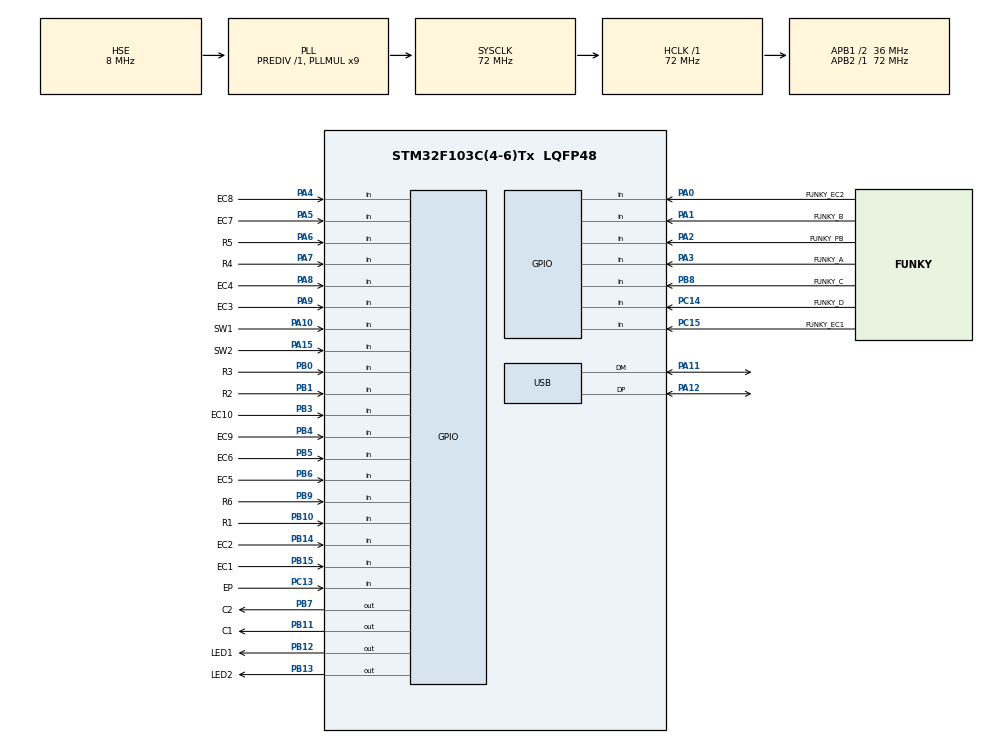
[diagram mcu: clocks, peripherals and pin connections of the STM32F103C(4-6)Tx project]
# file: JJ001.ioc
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Mcu.Family=STM32F1
Mcu.Name=STM32F103C(4-6)Tx
Mcu.Package=LQFP48
NVIC.PriorityGroup=NVIC_PRIORITYGROUP_4
NVIC.USB_LP_CAN1_RX0_IRQn=true\:0\:0\:false\:false\:true\:false\:true\:true
PA0-WKUP.GPIO_Label=FUNKY_EC2
PA0-WKUP.GPIO_PuPd=GPIO_PULLUP
PA0-WKUP.Signal=GPIO_Input
PA1.GPIO_Label=FUNKY_B
PA1.GPIO_PuPd=GPIO_PULLUP
PA1.Signal=GPIO_Input
PA10.GPIO_Label=SW1
PA10.GPIO_PuPd=GPIO_PULLUP
PA10.Signal=GPIO_Input
PA11.Mode=Device
PA11.Signal=USB_DM
PA12.Mode=Device
PA12.Signal=USB_DP
PA15.GPIO_Label=SW2
PA15.GPIO_PuPd=GPIO_PULLUP
PA15.Signal=GPIO_Input
PA2.GPIO_Label=FUNKY_PB
PA2.GPIO_PuPd=GPIO_PULLUP
PA2.Signal=GPIO_Input
PA3.GPIO_Label=FUNKY_A
PA3.GPIO_PuPd=GPIO_PULLUP
PA3.Signal=GPIO_Input
PA4.GPIO_Label=EC8
PA4.GPIO_PuPd=GPIO_PULLUP
PA4.Signal=GPIO_Input
PA5.GPIO_Label=EC7
PA5.GPIO_PuPd=GPIO_PULLUP
PA5.Signal=GPIO_Input
PA6.GPIO_Label=R5
PA6.GPIO_PuPd=GPIO_PULLUP
PA6.Signal=GPIO_Input
PA7.GPIO_Label=R4
PA7.GPIO_PuPd=GPIO_PULLUP
PA7.Signal=GPIO_Input
PA8.GPIO_Label=EC4
PA8.GPIO_PuPd=GPIO_PULLUP
PA8.Signal=GPIO_Input
PA9.GPIO_Label=EC3
PA9.GPIO_PuPd=GPIO_PULLUP
PA9.Signal=GPIO_Input
PB0.GPIO_Label=R3
PB0.GPIO_PuPd=GPIO_PULLUP
PB0.Signal=GPIO_Input
PB1.GPIO_Label=R2
PB1.GPIO_PuPd=GPIO_PULLUP
PB1.Signal=GPIO_Input
PB10.GPIO_Label=R1
PB10.GPIO_PuPd=GPIO_PULLUP
PB10.Signal=GPIO_Input
PB11.GPIO_Label=C1
PB11.GPIO_Speed=GPIO_SPEED_FREQ_HIGH
PB11.Signal=GPIO_Output
PB12.GPIO_Label=LED1
PB12.Signal=GPIO_Output
PB13.GPIO_Label=LED2
PB13.Signal=GPIO_Output
PB14.GPIO_Label=EC2
PB14.GPIO_PuPd=GPIO_PULLUP
PB14.Signal=GPIO_Input
PB15.GPIO_Label=EC1
PB15.GPIO_PuPd=GPIO_PULLUP
PB15.Signal=GPIO_Input
PB3.GPIO_Label=EC10
PB3.GPIO_PuPd=GPIO_PULLUP
PB3.Signal=GPIO_Input
PB4.GPIO_Label=EC9
PB4.GPIO_PuPd=GPIO_PULLUP
PB4.Signal=GPIO_Input
PB5.GPIO_Label=EC6
PB5.GPIO_PuPd=GPIO_PULLUP
PB5.Signal=GPIO_Input
PB6.GPIO_Label=EC5
PB6.GPIO_PuPd=GPIO_PULLUP
PB6.Signal=GPIO_Input
PB7.GPIO_Label=C2
PB7.GPIO_Speed=GPIO_SPEED_FREQ_HIGH
PB7.Signal=GPIO_Output
PB8.GPIO_Label=FUNKY_C
PB8.GPIO_PuPd=GPIO_PULLUP
PB8.Signal=GPIO_Input
PB9.GPIO_Label=R6
PB9.GPIO_PuPd=GPIO_PULLUP
PB9.Signal=GPIO_Input
PC13-TAMPER-RTC.GPIO_Label=EP
PC13-TAMPER-RTC.GPIO_PuPd=GPIO_PULLUP
PC13-TAMPER-RTC.Signal=GPIO_Input
PC14-OSC32_IN.GPIO_Label=FUNKY_D
PC14-OSC32_IN.GPIO_PuPd=GPIO_PULLUP
PC14-OSC32_IN.Signal=GPIO_Input
PC15-OSC32_OUT.GPIO_Label=FUNKY_EC1
PC15-OSC32_OUT.GPIO_PuPd=GPIO_PULLUP
PC15-OSC32_OUT.Signal=GPIO_Input
PD0-OSC_IN.Mode=HSE-External-Oscillator
PD0-OSC_IN.Signal=RCC_OSC_IN
PD1-OSC_OUT.Mode=HSE-External-Oscillator
PD1-OSC_OUT.Signal=RCC_OSC_OUT
ProjectManager.HeapSize=0x200
ProjectManager.StackSize=0x400
ProjectManager.TargetToolchain=STM32CubeIDE
RCC.AHBFreq_Value=72000000
RCC.APB1CLKDivider=RCC_HCLK_DIV2
RCC.APB1Freq_Value=36000000
RCC.APB1TimFreq_Value=72000000
RCC.APB2Freq_Value=72000000
RCC.APB2TimFreq_Value=72000000
RCC.HCLKFreq_Value=72000000
RCC.PLLMUL=RCC_PLL_MUL9
RCC.PLLSourceVirtual=RCC_PLLSOURCE_HSE
RCC.SYSCLKFreq_VALUE=72000000
RCC.SYSCLKSource=RCC_SYSCLKSOURCE_PLLCLK
RCC.USBFreq_Value=48000000
RCC.USBPrescaler=RCC_USBCLKSOURCE_PLL_DIV1_5
USB_DEVICE.CLASS_NAME_FS=CUSTOM_HID
USB_DEVICE.USBD_CUSTOM_HID_REPORT_DESC_SIZE=25
USB_DEVICE.VirtualMode=CustomHid
USB_DEVICE.VirtualModeFS=Custom_Hid_FS
VP_SYS_VS_ND.Mode=No_Debug
VP_USB_DEVICE_VS_USB_DEVICE_CUSTOM_HID_FS.Mode=CUSTOM_HID_FS
board=custom

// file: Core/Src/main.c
/* USER CODE BEGIN Header */
/**
  ******************************************************************************
  * @file           : main.c
  * @brief          : Main program body
  ******************************************************************************
  * @attention
  *
  * Copyright (c) 2022 STMicroelectronics.
  * All rights reserved.
  *
  * This software is licensed under terms that can be found in the LICENSE file
  * in the root directory of this software component.
  * If no LICENSE file comes with this software, it is provided AS-IS.
  *
  ******************************************************************************
  */
/* USER CODE END Header */
#include "main.h"
#include "usb_device.h"

void SystemClock_Config(void);
static void MX_GPIO_Init(void);

int main(void)
{

  /* MCU Configuration--------------------------------------------------------*/

  /* Reset of all peripherals, Initializes the Flash interface and the Systick. */
  HAL_Init();

  /* Configure the system clock */
  SystemClock_Config();

  /* Initialize all configured peripherals */
  MX_GPIO_Init();
  MX_USB_DEVICE_Init();
  /* USER CODE BEGIN 2 */
  APP_Init();

  /* USER CODE END 2 */

  /* Infinite loop */
  while (1)
  {

  }
}

void SystemClock_Config(void)
{
  RCC_OscInitTypeDef RCC_OscInitStruct = {0};
  RCC_ClkInitTypeDef RCC_ClkInitStruct = {0};
  RCC_PeriphCLKInitTypeDef PeriphClkInit = {0};

  /** Initializes the RCC Oscillators according to the specified parameters
  * in the RCC_OscInitTypeDef structure.
  */
  RCC_OscInitStruct.OscillatorType = RCC_OSCILLATORTYPE_HSE;
  RCC_OscInitStruct.HSEState = RCC_HSE_ON;
  RCC_OscInitStruct.HSEPredivValue = RCC_HSE_PREDIV_DIV1;
  RCC_OscInitStruct.HSIState = RCC_HSI_ON;
  RCC_OscInitStruct.PLL.PLLState = RCC_PLL_ON;
  RCC_OscInitStruct.PLL.PLLSource = RCC_PLLSOURCE_HSE;
  RCC_OscInitStruct.PLL.PLLMUL = RCC_PLL_MUL9;
  if (HAL_RCC_OscConfig(&RCC_OscInitStruct) != HAL_OK)
  {
    Error_Handler();
  }

  /** Initializes the CPU, AHB and APB buses clocks
  */
  RCC_ClkInitStruct.ClockType = RCC_CLOCKTYPE_HCLK|RCC_CLOCKTYPE_SYSCLK
                              |RCC_CLOCKTYPE_PCLK1|RCC_CLOCKTYPE_PCLK2;
  RCC_ClkInitStruct.SYSCLKSource = RCC_SYSCLKSOURCE_PLLCLK;
  RCC_ClkInitStruct.AHBCLKDivider = RCC_SYSCLK_DIV1;
  RCC_ClkInitStruct.APB1CLKDivider = RCC_HCLK_DIV2;
  RCC_ClkInitStruct.APB2CLKDivider = RCC_HCLK_DIV1;

  if (HAL_RCC_ClockConfig(&RCC_ClkInitStruct, FLASH_LATENCY_2) != HAL_OK)
  {
    Error_Handler();
  }
  PeriphClkInit.PeriphClockSelection = RCC_PERIPHCLK_USB;
  PeriphClkInit.UsbClockSelection = RCC_USBCLKSOURCE_PLL_DIV1_5;
  if (HAL_RCCEx_PeriphCLKConfig(&PeriphClkInit) != HAL_OK)
  {
    Error_Handler();
  }
}

static void MX_GPIO_Init(void)
{
  GPIO_InitTypeDef GPIO_InitStruct = {0};

  /* GPIO Ports Clock Enable */
  __HAL_RCC_GPIOC_CLK_ENABLE();
  __HAL_RCC_GPIOD_CLK_ENABLE();
  __HAL_RCC_GPIOA_CLK_ENABLE();
  __HAL_RCC_GPIOB_CLK_ENABLE();

  /*Configure GPIO pin Output Level */
  HAL_GPIO_WritePin(GPIOB, C1_Pin|LED1_Pin|LED2_Pin|C2_Pin, GPIO_PIN_RESET);

  /*Configure GPIO pins : EP_Pin FUNKY_D_Pin FUNKY_EC1_Pin */
  GPIO_InitStruct.Pin = EP_Pin|FUNKY_D_Pin|FUNKY_EC1_Pin;
  GPIO_InitStruct.Mode = GPIO_MODE_INPUT;
  GPIO_InitStruct.Pull = GPIO_PULLUP;
  HAL_GPIO_Init(GPIOC, &GPIO_InitStruct);

  /*Configure GPIO pins : FUNKY_EC2_Pin FUNKY_B_Pin FUNKY_PB_Pin FUNKY_A_Pin
                           EC8_Pin EC7_Pin R5_Pin R4_Pin
                           EC4_Pin EC3_Pin SW1_Pin SW2_Pin */
  GPIO_InitStruct.Pin = FUNKY_EC2_Pin|FUNKY_B_Pin|FUNKY_PB_Pin|FUNKY_A_Pin
                          |EC8_Pin|EC7_Pin|R5_Pin|R4_Pin
                          |EC4_Pin|EC3_Pin|SW1_Pin|SW2_Pin;
  GPIO_InitStruct.Mode = GPIO_MODE_INPUT;
  GPIO_InitStruct.Pull = GPIO_PULLUP;
  HAL_GPIO_Init(GPIOA, &GPIO_InitStruct);

  /*Configure GPIO pins : R3_Pin R2_Pin R1_Pin EC2_Pin
                           EC1_Pin EC10_Pin EC9_Pin EC6_Pin
                           EC5_Pin FUNKY_C_Pin R6_Pin */
  GPIO_InitStruct.Pin = R3_Pin|R2_Pin|R1_Pin|EC2_Pin
                          |EC1_Pin|EC10_Pin|EC9_Pin|EC6_Pin
                          |EC5_Pin|FUNKY_C_Pin|R6_Pin;
  GPIO_InitStruct.Mode = GPIO_MODE_INPUT;
  GPIO_InitStruct.Pull = GPIO_PULLUP;
  HAL_GPIO_Init(GPIOB, &GPIO_InitStruct);

  /*Configure GPIO pins : C1_Pin C2_Pin */
  GPIO_InitStruct.Pin = C1_Pin|C2_Pin;
  GPIO_InitStruct.Mode = GPIO_MODE_OUTPUT_PP;
  GPIO_InitStruct.Pull = GPIO_NOPULL;
  GPIO_InitStruct.Speed = GPIO_SPEED_FREQ_HIGH;
  HAL_GPIO_Init(GPIOB, &GPIO_InitStruct);

  /*Configure GPIO pins : LED1_Pin LED2_Pin */
  GPIO_InitStruct.Pin = LED1_Pin|LED2_Pin;
  GPIO_InitStruct.Mode = GPIO_MODE_OUTPUT_PP;
  GPIO_InitStruct.Pull = GPIO_NOPULL;
  GPIO_InitStruct.Speed = GPIO_SPEED_FREQ_LOW;
  HAL_GPIO_Init(GPIOB, &GPIO_InitStruct);

}

void Error_Handler(void)
{
  __disable_irq();
  while (1)
  {
  }
}
